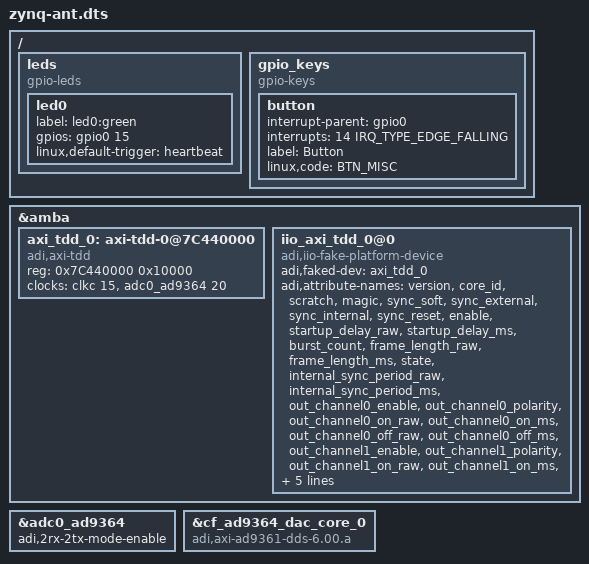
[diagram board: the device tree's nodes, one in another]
// SPDX-License-Identifier: GPL-2.0
/*
 *
 * hdl_project: <ant>
 * board_revision: <A>
 *
 * Copyright (C) 2016-2019 MicroPhase Inc.
 */
/dts-v1/;
#include "zynq-ant.dtsi"


// &axi_i2c0 {
// 	current_limiter@5a {
// 		compatible = "adi,adm1177";
// 		reg = <0x5a>;
// 		adi,r-sense-mohm = <50>; /* 50 mOhm */
// 		adi,shutdown-threshold-ma = <1059>; /* 1.059 A */
// 		adi,vrange-high-enable;
// 	};
// };

&amba {
       axi_tdd_0: axi-tdd-0@7C440000 {
               compatible = "adi,axi-tdd";
               reg = <0x7C440000 0x10000>;
               clocks = <&clkc 15>, <&adc0_ad9364 20>;
               clock-names = "s_axi_aclk", "intf_clk";
       };

       iio_axi_tdd_0@0 {
               compatible = "adi,iio-fake-platform-device";
               adi,faked-dev = <&axi_tdd_0>;
               adi,attribute-names =
               "version", "core_id", "scratch", "magic",
               "sync_soft", "sync_external", "sync_internal", "sync_reset",
               "enable", "startup_delay_raw", "startup_delay_ms",
               "burst_count", "frame_length_raw", "frame_length_ms",
               "state", "internal_sync_period_raw", "internal_sync_period_ms",
               "out_channel0_enable", "out_channel0_polarity",
               "out_channel0_on_raw", "out_channel0_on_ms",
               "out_channel0_off_raw", "out_channel0_off_ms",
               "out_channel1_enable", "out_channel1_polarity",
               "out_channel1_on_raw", "out_channel1_on_ms",
               "out_channel1_off_raw", "out_channel1_off_ms",
               "out_channel2_enable", "out_channel2_polarity",
               "out_channel2_on_raw", "out_channel2_on_ms",
               "out_channel2_off_raw", "out_channel2_off_ms";
               label = "iio-axi-tdd-0";
       };

};

&adc0_ad9364 {
	/* This property is controlled by u-boot environment. */
	adi,2rx-2tx-mode-enable;
};

&cf_ad9364_dac_core_0 {
	/* This property is controlled by u-boot environment. */
	compatible = "adi,axi-ad9361-dds-6.00.a";
};


/ {
	
	leds {
		compatible = "gpio-leds";
		led0 {
			label = "led0:green";
			gpios = <&gpio0 15 0>;
			linux,default-trigger = "heartbeat";
		};
	};

	gpio_keys {
		compatible = "gpio-keys";
		#address-cells = <1>;
		#size-cells = <0>;

		button {
			interrupt-parent = <&gpio0>;
			interrupts = <14 IRQ_TYPE_EDGE_FALLING>;
			label = "Button";
			linux,code = <BTN_MISC>;
		};

	};
/*
        one-bit-adc-dac@0 {
                compatible = "adi,one-bit-adc-dac";

                #address-cells = <1>;
                #size-cells = <0>;

                in-gpios = <&gpio0 73 GPIO_ACTIVE_HIGH>;
                out-gpios = <&gpio0 74 GPIO_ACTIVE_HIGH>;

                channel@0 {
                        reg = <0>;
                        label = "txdata";
                };

                channel@1 {
                        reg = <1>;
                        label = "orange";
                };
        };
*/
};


	
